# STM32H7P4 register map
File version: 2.0.0
CPU: CM7 r1p2, little endian, MPU, FPU, 4 interrupt priority bits
Registers are 32-bit, read-write, reset 0x0 unless marked. A register's access mark holds for its fields unless they carry their own. Offsets are from the block's base; [hi:lo] are bit positions; {n}, {i} and the like mark numbered series; 'fields as' and 'values as' point back to an identical list.

## SBS — SBS register block
Base 0x58000400
0x00 SBS_BOOTSR ro — SBS boot status register
  [31:0] INITVTOR — Initial vector for Cortex-M7
0x10 SBS_HDPLCR reset 0xB4 — SBS hide protection control register
  [7:0] INCR_HDPL — Increment HDPL
0x14 SBS_HDPLSR ro (reset mask 0xFFFFFF00) — SBS hide protection status register
  [7:0] HDPL — Hide protection level
    180=HDPL0, corresponding to ST-RSS (default when device is CLOSE); 81=HDPL1; 138=HDPL2
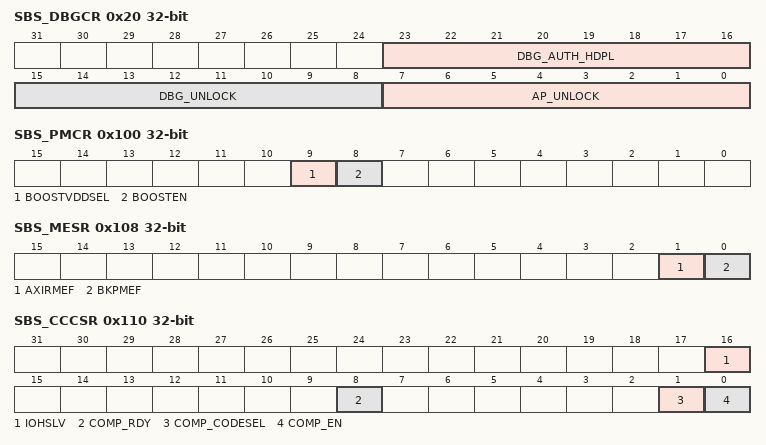
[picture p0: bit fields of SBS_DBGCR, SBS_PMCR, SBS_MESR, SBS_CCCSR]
0x20 SBS_DBGCR — SBS debug control register
  [23:16] DBG_AUTH_HDPL — Authenticated debug hide protection level
    81=HDPL1; 138=HDPL2; 111=HDPL3
  [15:8] DBG_UNLOCK — Debug unlock
  [7:0] AP_UNLOCK — Access port unlock
0x24 SBS_DBGLOCKR reset 0xB4 — SBS debug lock register
  [7:0] DBGCFG_LOCK — Debug configuration lock
    180=Writes to SBS_DBGCR allowed (default)
0x34 SBS_RSSCMDR — SBS RSS command register
  [15:0] RSSCMD — RSS command
0x100 SBS_PMCR — SBS product mode and configuration register
  [9] BOOSTVDDSEL — Booster Vless thansub>DDless than/sub> selection
    0=Vless thansub>DDAless than/sub> selected as analog switch booster voltage supply (when BOOSTEN bit is cleared); 1=Vless thansub>DDless than/sub> selected as analog switch booster voltage supply
  [8] BOOSTEN — Booster enable
    0=Booster disabled; 1=Booster enabled
0x104 SBS_FPUIMR reset 0x1F — SBS FPU interrupt mask register
  [5:0] FPU_IE — FPU interrupt enable
0x108 SBS_MESR ro — SBS memory erase status register
  [1] AXIRMEF — AXISRAM1 memory erase flag
    0=Automatic erase of AXISRAM1 memory ongoing; 1=Automatic erase of AXISRAM1 memory done
  [0] BKPMEF — Backup SRAM memory erase flag
    0=Automatic erase of BKPRAM memory ongoing; 1=Automatic erase of BKPRAM memory done
0x110 SBS_CCCSR — SBS I/O compensation cell control and status register
  [16] IOHSLV — I/O high speed at low voltage
    0=No I/O speed optimization when device voltage is low; 1=I/O speed optimized when device voltage is low, if VDDIO_HSLV user option is set (no effect otherwise)
  [8] COMP_RDY ro — Compensation cell ready
    0=I/O compensation cell not ready; 1=I/O compensation cell ready
  [1] COMP_CODESEL — Compensation cell code selection
    0=Code from the cell (available in the SBS_CCVALR); 1=Code from the SBS software value register (SBS_CCSWVALR)
  [0] COMP_EN — Compensation cell enable
    0=Compensation cell disabled; 1=Compensation cell enabled
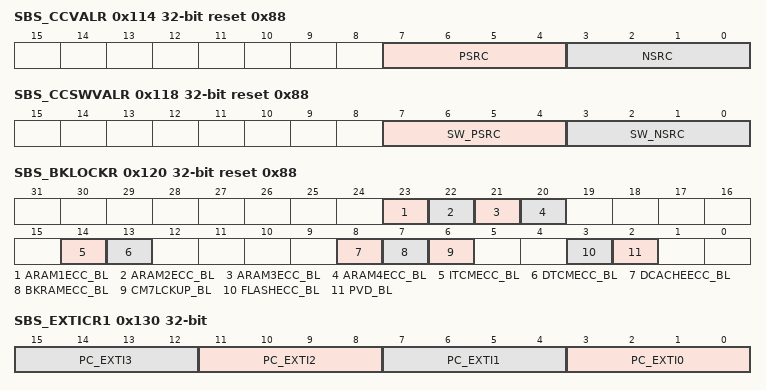
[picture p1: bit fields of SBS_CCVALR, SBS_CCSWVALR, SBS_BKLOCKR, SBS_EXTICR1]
0x114 SBS_CCVALR ro reset 0x88 — SBS compensation cell for I/Os value register
  [7:4] PSRC — PMOS transistors slew-rate compensation
  [3:0] NSRC — NMOS transistors slew-rate compensation
0x118 SBS_CCSWVALR reset 0x88 — SBS compensation cell for I/Os software value register
  [7:4] SW_PSRC — Software PMOS transistors slew-rate compensation
  [3:0] SW_NSRC — Software NMOS transistors slew-rate compensation
0x120 SBS_BKLOCKR reset 0x88 — SBS break lock register
  [23] ARAM1ECC_BL — AXISRAM1 ECC error break lock
    0=AXISRAM1 ECC double error detection flag disconnected from TIM1/8/5/16/17/20 and HRTIMER1/2 break inputs; 1=AXISRAM1 ECC double error detection flag connected to TIM1/8/15/16/17/20 and HRTIMER1/2break inputs
  [22] ARAM2ECC_BL — AXISRAM2 ECC error break lock
    0=AXISRAM2 ECC double error detection flag disconnected from TIM1/8/5/16/17/20 and HRTIMER1/2 break inputs; 1=AXISRAM2 ECC double error detection flag connected to TIM1/8/15/16/17/20 and HRTIMER1/2 break inputs
  [21] ARAM3ECC_BL — AXISRAM3 ECC error break lock
    0=AXISRAM3 ECC double error detection flag disconnected from TIM1/8/15/16/17/20 and HRTIMER1/2 break inputs; 1=AXISRAM3 ECC double error detection flag connected to TIM1/8/15/16/17/20 and HRTIMER1/2 break inputs
  [20] ARAM4ECC_BL — AXISRAM4 ECC error break lock
    0=AXISRAM4 ECC double error detection flag disconnected from TIM1/8/15/16/17/20 and HRTIMER1/2 break inputs; 1=AXISRAM4 ECC double error detection flag connected to TIM1/8/15/16/17/20 and HRTIMER1/2 break inputs
  [14] ITCMECC_BL — ITCM ECC error break lock
    0=ITCM ECC double error detection flag disconnected from TIM1/8/15/16/17/20 and HRTIMER1/2 break inputs; 1=ITCM ECC double error detection flag connected to TIM1/8/15/16/17/20 and HRTIMER1/2 breakinputs
  [13] DTCMECC_BL — DTCM ECC error break lock
    0=DTCM ECC double error detection flag disconnected from TIM1/8/15/16/17/20 and HRTIMER1/2 break inputs; 1=DTCM ECC double error detection flag connected to TIM1/8/15/16/17/20 and HRTIMER1/2 break inputs
  [8] DCACHEECC_BL — D-Cache ECC error break lock
    0=D-Cache ECC double error detection flag disconnected from TIM1/8/15/16/17/20 and HRTIMER1/2 break inputs; 1=Cache ECC double error detection flag connected to TIM1/8/15/16/17/20 and HRTIMER1/2 breakinputs
  [7] BKRAMECC_BL — Backup RAM ECC error break lock
    0=Backup RAM ECC double error detection flag disconnected from TIM1/8/15/16/17/20 and HRTIMER1/2 break inputs; 1=Backup RAM ECC double error detection flag connected to TIM1/8/15/16/17/20 and HRTIMER1/2 break inputs
  [6] CM7LCKUP_BL — Cortex-M7 lockup break lock
    0=Cortex-M7 lockup output disconnected from TIM1/8/15/16/17/20 and HRTIMER1/2 break inputs; 1=Cortex-M7 lockup output connected to TIM1/8/15/16/17/20 and HRTIMER1/2 break inputs
  [3] FLASHECC_BL — Flash ECC error break lock
    0=FLASH ECC double error detection flag disconnected from TIM1/8/15/16/17/20 and HRTIMER1/2 break inputs; 1=FLASH ECC double error detection flag connected to TIM1/8/15/16/17/20 and HRTIMER1/2 break inputs
  [2] PVD_BL — PVD break lock
    0=PVD interrupt disconnected from TIM1/8/15/16/17/20 and HRTIMER1/2 break inputs; 1=PVD output connected to TIM1/8/15/16/17/20 and HRTIMER1/2 break inputs
0x130 SBS_EXTICR1 ro — SBS external interrupt configuration register 1
  [4n+3:4n] PC_EXTI{n} (n=0..3) — Port configuration for EXTI{n}
    0=PA{n} pin; 1=PB{n} pin; 2=PC{n} pin; 3=PD{n} pin; 4=PE{n} pin; 5=PF{n} pin; 6=PG{n} pin; 7=PH{n} pin; 8=PI{n} pin
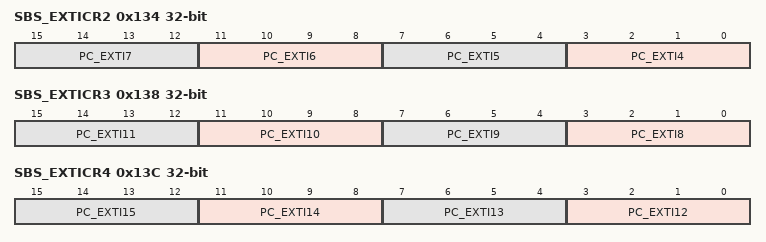
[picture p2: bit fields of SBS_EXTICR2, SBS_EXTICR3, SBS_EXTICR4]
0x134 SBS_EXTICR2 ro — SBS external interrupt configuration register 2
  [4n-13:4n-16] PC_EXTI{n} (n=4..7) — Port configuration for EXTI{n}
    values as SBS_EXTICR1.PC_EXTI0
0x138 SBS_EXTICR3 ro — SBS external interrupt configuration register 3
  [4n-29:4n-32] PC_EXTI{n} (n=8..11) — Port configuration for EXTI{n}
    values as SBS_EXTICR1.PC_EXTI0
0x13C SBS_EXTICR4 ro — SBS external interrupt configuration register 4
  [4n-45:4n-48] PC_EXTI{n} (n=12..15) — Port configuration for EXTI{n}
    values as SBS_EXTICR1.PC_EXTI0
